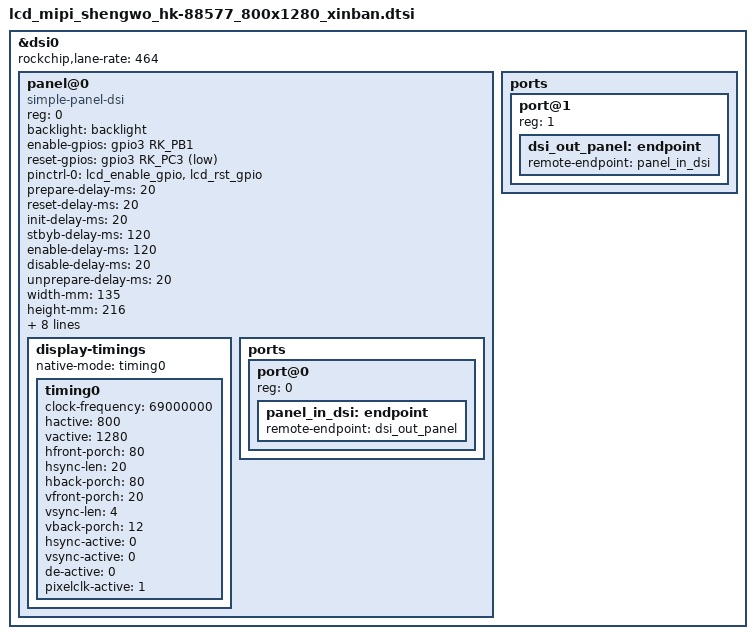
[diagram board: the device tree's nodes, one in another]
/*
* incar mipi lcd
*/
&dsi0 {
	status = "okay";
	rockchip,lane-rate = <464>;
	panel@0 {
		compatible = "simple-panel-dsi";
		reg = <0>;
		backlight = <&backlight>;
		//power-supply=<&vcc_3v3>;
		enable-gpios = <&gpio3 RK_PB1 GPIO_ACTIVE_HIGH>;
		//stbyb-gpios = <&gpio0 RK_PC0 GPIO_ACTIVE_LOW>;
		reset-gpios = <&gpio3 RK_PC3 GPIO_ACTIVE_LOW>;
		pinctrl-names = "default";
		pinctrl-0 = <&lcd_enable_gpio>, <&lcd_rst_gpio>;

		prepare-delay-ms = <20>;
		reset-delay-ms = <20>;
		init-delay-ms = <20>;
		stbyb-delay-ms = <120>;
		enable-delay-ms = <120>;
		disable-delay-ms = <20>;
		unprepare-delay-ms = <20>;

		width-mm = <135>;
		height-mm = <216>;

		dsi,flags = <(MIPI_DSI_MODE_VIDEO | MIPI_DSI_MODE_VIDEO_BURST |
			      MIPI_DSI_MODE_LPM | MIPI_DSI_MODE_EOT_PACKET)>;
		dsi,format = <MIPI_DSI_FMT_RGB888>;
		dsi,lanes = <4>;

		panel-init-sequence = [
            39 00  03 E0 AB BA
            39 00  03 E1 BA AB
            15 00  02 B0 00
            39 00  05 B1 10 01 47 FF
            39 00  07 B2 1E 04 04 50 50 14
            39 00  04 B3 56 D3 00
            39 00  04 B4 33 30 04
            39 00  08 B6 00 00 00 10 00 10 00
            39 00  07 C8 21 00 31 42 34 16
            39 00  03 CA 4B 43
            39 00  05 CC 2E 02 04 08
            39 00  05 D2 E3 2B 38 00//4L
            39 00  09 E6 80 01 FF FF FF FF FF FF
            39 00  06 F0 12 03 20 00 FF
            15 00  02 F3 00
			05 78 01 11  
			05 0a 01 29 


			 
		];

		panel-exit-sequence = [
			05 01 01 28
			05 03 01 10
		];

		display-timings {
			native-mode = <&timing0>;
			timing0: timing0 {
				clock-frequency = <69000000>;
				hactive = <800>;
				vactive = <1280>;
				hfront-porch = <80>;
				hsync-len = <20>;
				hback-porch = <80>;
				vfront-porch = <20>;
				vsync-len = <4>;
				vback-porch = <12>;
				hsync-active = <0>;
				vsync-active = <0>;
				de-active = <0>;
				pixelclk-active = <1>;
			};
		};
		ports {
			#address-cells = <1>;
			#size-cells = <0>;

			port@0 {
				reg = <0>;
				panel_in_dsi: endpoint {
					remote-endpoint = <&dsi_out_panel>;
				};
			};
		};
	};

	ports {
		#address-cells = <1>;
		#size-cells = <0>;

		port@1 {
			reg = <1>;
			dsi_out_panel: endpoint {
				remote-endpoint = <&panel_in_dsi>;
			};
		};
	};
};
